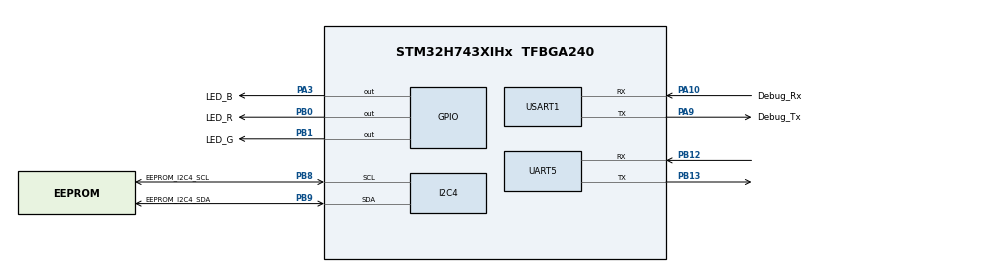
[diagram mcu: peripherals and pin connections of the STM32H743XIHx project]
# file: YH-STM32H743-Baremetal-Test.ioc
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CORTEX_M7.CPU_DCache=Enabled
CORTEX_M7.CPU_ICache=Enabled
CORTEX_M7.default_mode_Activation=0
FREERTOS.Tasks01=defaultTask,24,128,StartDefaultTask,Default,NULL,Dynamic,NULL,NULL;myTask02,26,512,StartTask02,As weak,NULL,Static,myTask02Buffer,myTask02ControlBlock;myTask03,27,512,StartTask03,As weak,NULL,Static,myTask03Buffer,myTask03ControlBlock;myTask04,12,512,StartTask04,As weak,NULL,Static,myTask04Buffer,myTask04ControlBlock;MB_Slave_Task,28,512,MB_Slave_Task_Entry,As weak,NULL,Static,MB_Slave_TaskBuffer,MB_Slave_TaskControlBlock
FREERTOS.configUSE_IDLE_HOOK=1
FREERTOS.configUSE_NEWLIB_REENTRANT=0
FREERTOS.configUSE_TICK_HOOK=1
I2C4.Timing=0x10C0ECFF
Mcu.Family=STM32H7
Mcu.Name=STM32H743XIHx
Mcu.Package=TFBGA240
NVIC.I2C4_ER_IRQn=true\:5\:0\:false\:false\:true\:true\:true\:true\:true
NVIC.I2C4_EV_IRQn=true\:5\:0\:false\:false\:true\:true\:true\:true\:true
NVIC.PriorityGroup=NVIC_PRIORITYGROUP_4
NVIC.TIM6_DAC_IRQn=true\:15\:0\:false\:false\:true\:false\:false\:true\:true
NVIC.TIM7_IRQn=true\:8\:0\:true\:false\:true\:true\:true\:true\:true
NVIC.TimeBase=TIM6_DAC_IRQn
NVIC.TimeBaseIP=TIM6
NVIC.UART5_IRQn=true\:5\:0\:false\:false\:true\:true\:true\:true\:true
NVIC.USART1_IRQn=true\:5\:0\:false\:false\:true\:true\:true\:true\:true
PA10.GPIO_Label=Debug_Rx
PA10.GPIO_Speed=GPIO_SPEED_FREQ_MEDIUM
PA10.Mode=Asynchronous
PA10.Signal=USART1_RX
PA13\ (JTMS/SWDIO).Mode=Serial_Wire
PA13\ (JTMS/SWDIO).Signal=DEBUG_JTMS-SWDIO
PA14\ (JTCK/SWCLK).Mode=Serial_Wire
PA14\ (JTCK/SWCLK).Signal=DEBUG_JTCK-SWCLK
PA3.GPIO_Label=LED_B
PA3.PinState=GPIO_PIN_SET
PA3.Signal=GPIO_Output
PA9.GPIO_Label=Debug_Tx
PA9.GPIO_Speed=GPIO_SPEED_FREQ_MEDIUM
PA9.Mode=Asynchronous
PA9.Signal=USART1_TX
PB0.GPIO_Label=LED_R
PB0.PinState=GPIO_PIN_SET
PB0.Signal=GPIO_Output
PB1.GPIO_Label=LED_G
PB1.PinState=GPIO_PIN_SET
PB1.Signal=GPIO_Output
PB12.Mode=Asynchronous
PB12.Signal=UART5_RX
PB13.Mode=Asynchronous
PB13.Signal=UART5_TX
PB8.GPIO_Label=EEPROM_I2C4_SCL
PB8.GPIO_Speed=GPIO_SPEED_FREQ_HIGH
PB8.Mode=I2C
PB8.Signal=I2C4_SCL
PB9.GPIO_Label=EEPROM_I2C4_SDA
PB9.GPIO_Speed=GPIO_SPEED_FREQ_HIGH
PB9.Mode=I2C
PB9.Signal=I2C4_SDA
PH0-OSC_IN\ (PH0).Mode=HSE-External-Oscillator
PH0-OSC_IN\ (PH0).Signal=RCC_OSC_IN
PH1-OSC_OUT\ (PH1).Mode=HSE-External-Oscillator
PH1-OSC_OUT\ (PH1).Signal=RCC_OSC_OUT
ProjectManager.HeapSize=0x200
ProjectManager.StackSize=0x400
ProjectManager.TargetToolchain=MDK-ARM V5.32
RCC.ADCFreq_Value=50390625
RCC.APB1Freq_Value=100000000
RCC.APB2Freq_Value=100000000
RCC.APB3Freq_Value=100000000
RCC.APB4Freq_Value=100000000
RCC.CortexFreq_Value=400000000
RCC.D1PPRE=RCC_APB3_DIV2
RCC.D2PPRE1=RCC_APB1_DIV2
RCC.D2PPRE2=RCC_APB2_DIV2
RCC.D3PPRE=RCC_APB4_DIV2
RCC.DIVM1=2
RCC.DIVN1=64
RCC.HCLKFreq_Value=200000000
RCC.HPRE=RCC_HCLK_DIV2
RCC.PLLFRACN=0
RCC.PLLSourceVirtual=RCC_PLLSOURCE_HSE
RCC.SYSCLKFreq_VALUE=400000000
RCC.SYSCLKSource=RCC_SYSCLKSOURCE_PLLCLK
RCC.USBFreq_Value=400000000
TIM7.Period=1750-1
TIM7.Prescaler=200-1
USART1.VirtualMode-Asynchronous=VM_ASYNC
VP_FREERTOS_VS_CMSIS_V2.Mode=CMSIS_V2
VP_MEMORYMAP_VS_MEMORYMAP.Mode=CurAppReg
VP_SYS_VS_tim6.Mode=TIM6
VP_TIM7_VS_ClockSourceINT.Mode=Enable_Timer
board=custom

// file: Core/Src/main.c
/* USER CODE BEGIN Header */
/**
  ******************************************************************************
  * @file           : main.c
  * @brief          : Main program body
  ******************************************************************************
  * @attention
  *
  * Copyright (c) 2024 STMicroelectronics.
  * All rights reserved.
  *
  * This software is licensed under terms that can be found in the LICENSE file
  * in the root directory of this software component.
  * If no LICENSE file comes with this software, it is provided AS-IS.
  *
  ******************************************************************************
  */
/* USER CODE END Header */
#include "main.h"
#include "cmsis_os.h"
#include "i2c.h"
#include "memorymap.h"
#include "tim.h"
#include "usart.h"
#include "gpio.h"

/* USER CODE BEGIN Includes */
#include "I2c4.h"
// freemodbus
#include "mb.h"
#include "mbutils.h"
/* USER CODE END Includes */

void SystemClock_Config(void);
void MX_FREERTOS_Init(void);

int main(void)
{

  /* Enable the CPU Cache */

  /* Enable I-Cache---------------------------------------------------------*/
  SCB_EnableICache();

  /* Enable D-Cache---------------------------------------------------------*/
  SCB_EnableDCache();

  /* MCU Configuration--------------------------------------------------------*/

  /* Reset of all peripherals, Initializes the Flash interface and the Systick. */
  HAL_Init();

  /* Configure the system clock */
  SystemClock_Config();

  /* Initialize all configured peripherals */
  MX_GPIO_Init();
  MX_USART1_UART_Init();
  MX_I2C4_Init();
  MX_TIM7_Init();
  MX_UART5_Init();
  /* USER CODE BEGIN 2 */
  #if 1
  I2C_Test();// 测试结果是可以的
  Print_CPU_INFO();
  #endif
    // freemodbus init
  	eMBInit(MB_RTU, 0x01, 0x03, 115200, MB_PAR_NONE);
  	eMBEnable();
  /* USER CODE END 2 */

  /* Init scheduler */
  osKernelInitialize();

  /* Call init function for freertos objects (in cmsis_os2.c) */
  MX_FREERTOS_Init();

  /* Start scheduler */
  osKernelStart();

  /* We should never get here as control is now taken by the scheduler */

  /* Infinite loop */
  while (1)
  {

  }
}

void SystemClock_Config(void)
{
  RCC_ClkInitTypeDef RCC_ClkInitStruct = {0};

  /** Supply configuration update enable
  */
  HAL_PWREx_ConfigSupply(PWR_LDO_SUPPLY);

  /** Configure the main internal regulator output voltage
  */
  __HAL_PWR_VOLTAGESCALING_CONFIG(PWR_REGULATOR_VOLTAGE_SCALE1);

  while(!__HAL_PWR_GET_FLAG(PWR_FLAG_VOSRDY)) {}

  /** Initializes the CPU, AHB and APB buses clocks
  */
  RCC_ClkInitStruct.ClockType = RCC_CLOCKTYPE_HCLK|RCC_CLOCKTYPE_SYSCLK
                              |RCC_CLOCKTYPE_PCLK1|RCC_CLOCKTYPE_PCLK2
                              |RCC_CLOCKTYPE_D3PCLK1|RCC_CLOCKTYPE_D1PCLK1;
  RCC_ClkInitStruct.SYSCLKSource = RCC_SYSCLKSOURCE_PLLCLK;
  RCC_ClkInitStruct.SYSCLKDivider = RCC_SYSCLK_DIV1;
  RCC_ClkInitStruct.AHBCLKDivider = RCC_HCLK_DIV2;
  RCC_ClkInitStruct.APB3CLKDivider = RCC_APB3_DIV2;
  RCC_ClkInitStruct.APB1CLKDivider = RCC_APB1_DIV2;
  RCC_ClkInitStruct.APB2CLKDivider = RCC_APB2_DIV2;
  RCC_ClkInitStruct.APB4CLKDivider = RCC_APB4_DIV2;

  if (HAL_RCC_ClockConfig(&RCC_ClkInitStruct, FLASH_LATENCY_2) != HAL_OK)
  {
    Error_Handler();
  }
}

void HAL_TIM_PeriodElapsedCallback(TIM_HandleTypeDef *htim)
{
  if (htim->Instance == TIM6) {
    HAL_IncTick();
  }
  /* USER CODE BEGIN Callback 1 */
  if (htim->Instance == TIM7) {
    prvvTIMERExpiredISR();
  }
  /* USER CODE END Callback 1 */
}

void Error_Handler(void)
{
  __disable_irq();
  while (1)
  {
  }
}

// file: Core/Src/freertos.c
/* USER CODE BEGIN Header */
/**
  ******************************************************************************
  * File Name          : freertos.c
  * Description        : Code for freertos applications
  ******************************************************************************
  * @attention
  *
  * Copyright (c) 2024 STMicroelectronics.
  * All rights reserved.
  *
  * This software is licensed under terms that can be found in the LICENSE file
  * in the root directory of this software component.
  * If no LICENSE file comes with this software, it is provided AS-IS.
  *
  ******************************************************************************
  */
/* USER CODE END Header */

#include "FreeRTOS.h"
#include "task.h"
#include "main.h"
#include "cmsis_os.h"

typedef StaticTask_t osStaticThreadDef_t;

/* Definitions for defaultTask */
osThreadId_t defaultTaskHandle;
const osThreadAttr_t defaultTask_attributes = {
  .name = "defaultTask",
  .stack_size = 128 * 4,
  .priority = (osPriority_t) osPriorityNormal,
};
/* Definitions for myTask02 */
osThreadId_t myTask02Handle;
uint32_t myTask02Buffer[ 512 ];
osStaticThreadDef_t myTask02ControlBlock;
const osThreadAttr_t myTask02_attributes = {
  .name = "myTask02",
  .cb_mem = &myTask02ControlBlock,
  .cb_size = sizeof(myTask02ControlBlock),
  .stack_mem = &myTask02Buffer[0],
  .stack_size = sizeof(myTask02Buffer),
  .priority = (osPriority_t) osPriorityNormal2,
};
/* Definitions for myTask03 */
osThreadId_t myTask03Handle;
uint32_t myTask03Buffer[ 512 ];
osStaticThreadDef_t myTask03ControlBlock;
const osThreadAttr_t myTask03_attributes = {
  .name = "myTask03",
  .cb_mem = &myTask03ControlBlock,
  .cb_size = sizeof(myTask03ControlBlock),
  .stack_mem = &myTask03Buffer[0],
  .stack_size = sizeof(myTask03Buffer),
  .priority = (osPriority_t) osPriorityNormal3,
};
/* Definitions for myTask04 */
osThreadId_t myTask04Handle;
uint32_t myTask04Buffer[ 512 ];
osStaticThreadDef_t myTask04ControlBlock;
const osThreadAttr_t myTask04_attributes = {
  .name = "myTask04",
  .cb_mem = &myTask04ControlBlock,
  .cb_size = sizeof(myTask04ControlBlock),
  .stack_mem = &myTask04Buffer[0],
  .stack_size = sizeof(myTask04Buffer),
  .priority = (osPriority_t) osPriorityLow4,
};
/* Definitions for MB_Slave_Task */
osThreadId_t MB_Slave_TaskHandle;
uint32_t MB_Slave_TaskBuffer[ 512 ];
osStaticThreadDef_t MB_Slave_TaskControlBlock;
const osThreadAttr_t MB_Slave_Task_attributes = {
  .name = "MB_Slave_Task",
  .cb_mem = &MB_Slave_TaskControlBlock,
  .cb_size = sizeof(MB_Slave_TaskControlBlock),
  .stack_mem = &MB_Slave_TaskBuffer[0],
  .stack_size = sizeof(MB_Slave_TaskBuffer),
  .priority = (osPriority_t) osPriorityNormal4,
};

void StartDefaultTask(void *argument);
void StartTask02(void *argument);
void StartTask03(void *argument);
void StartTask04(void *argument);
void MB_Slave_Task_Entry(void *argument);

void MX_FREERTOS_Init(void); /* (MISRA C 2004 rule 8.1) */

/* Hook prototypes */
void vApplicationIdleHook(void);
void vApplicationTickHook(void);

/* USER CODE BEGIN 2 */
void vApplicationIdleHook( void )
{
   /* vApplicationIdleHook() will only be called if configUSE_IDLE_HOOK is set
   to 1 in FreeRTOSConfig.h. It will be called on each iteration of the idle
   task. It is essential that code added to this hook function never attempts
   to block in any way (for example, call xQueueReceive() with a block time
   specified, or call vTaskDelay()). If the application makes use of the
   vTaskDelete() API function (as this demo application does) then it is also
   important that vApplicationIdleHook() is permitted to return to its calling
   function, because it is the responsibility of the idle task to clean up
   memory allocated by the kernel to any task that has since been deleted. */
}
/* USER CODE END 2 */

/* USER CODE BEGIN 3 */
void vApplicationTickHook( void )
{
   /* This function will be called by each tick interrupt if
   configUSE_TICK_HOOK is set to 1 in FreeRTOSConfig.h. User code can be
   added here, but the tick hook is called from an interrupt context, so
   code must not attempt to block, and only the interrupt safe FreeRTOS API
   functions can be used (those that end in FromISR()). */
}
/* USER CODE END 3 */

void MX_FREERTOS_Init(void) {

  /* Create the thread(s) */
  /* creation of defaultTask */
  defaultTaskHandle = osThreadNew(StartDefaultTask, NULL, &defaultTask_attributes);

  /* creation of myTask02 */
  myTask02Handle = osThreadNew(StartTask02, NULL, &myTask02_attributes);

  /* creation of myTask03 */
  myTask03Handle = osThreadNew(StartTask03, NULL, &myTask03_attributes);

  /* creation of myTask04 */
  myTask04Handle = osThreadNew(StartTask04, NULL, &myTask04_attributes);

  /* creation of MB_Slave_Task */
  MB_Slave_TaskHandle = osThreadNew(MB_Slave_Task_Entry, NULL, &MB_Slave_Task_attributes);

}

void StartDefaultTask(void *argument)
{
  for(;;)
  {
    osDelay(1);
  }
}

__weak void StartTask02(void *argument)
{
  for(;;)
  {
    osDelay(1);
  }
}

__weak void StartTask03(void *argument)
{
  for(;;)
  {
    osDelay(1);
  }
}

__weak void StartTask04(void *argument)
{
  for(;;)
  {
    osDelay(1);
  }
}

__weak void MB_Slave_Task_Entry(void *argument)
{
  for(;;)
  {
    osDelay(1);
  }
}
